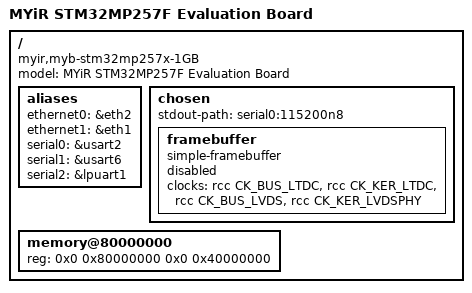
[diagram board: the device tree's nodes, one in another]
// SPDX-License-Identifier: (GPL-2.0-or-later OR BSD-3-Clause)
/*
 * Copyright (C) MYiRi 2024 - All Rights Reserved
 */

 /dts-v1/;

 #include "myb-stm32mp257x-base.dtsi"
 #include "myb-stm32mp257x-1GB-resmem.dtsi"
 
 / {
     model = "MYiR STM32MP257F Evaluation Board";
     compatible = "myir,myb-stm32mp257x-1GB", "st,stm32mp257f-ev1", "st,stm32mp257";
 
     aliases {
         ethernet0 = &eth2;
         ethernet1 = &eth1;
         serial0 = &usart2;
         serial1 = &usart6;
         serial2 = &lpuart1;
     };
 
     chosen {
         stdout-path = "serial0:115200n8";
         #address-cells = <2>;
         #size-cells = <2>;
         ranges;
 
         framebuffer {
             compatible = "simple-framebuffer";
             clocks = <&rcc CK_BUS_LTDC>, <&rcc CK_KER_LTDC>,
                  <&rcc CK_BUS_LVDS>, <&rcc CK_KER_LVDSPHY>;
             status = "disabled";
         };
     };
 
     memory@80000000 {
         device_type = "memory";
         reg = <0x0 0x80000000 0x0 0x40000000>;
     };
 
 
 };
 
